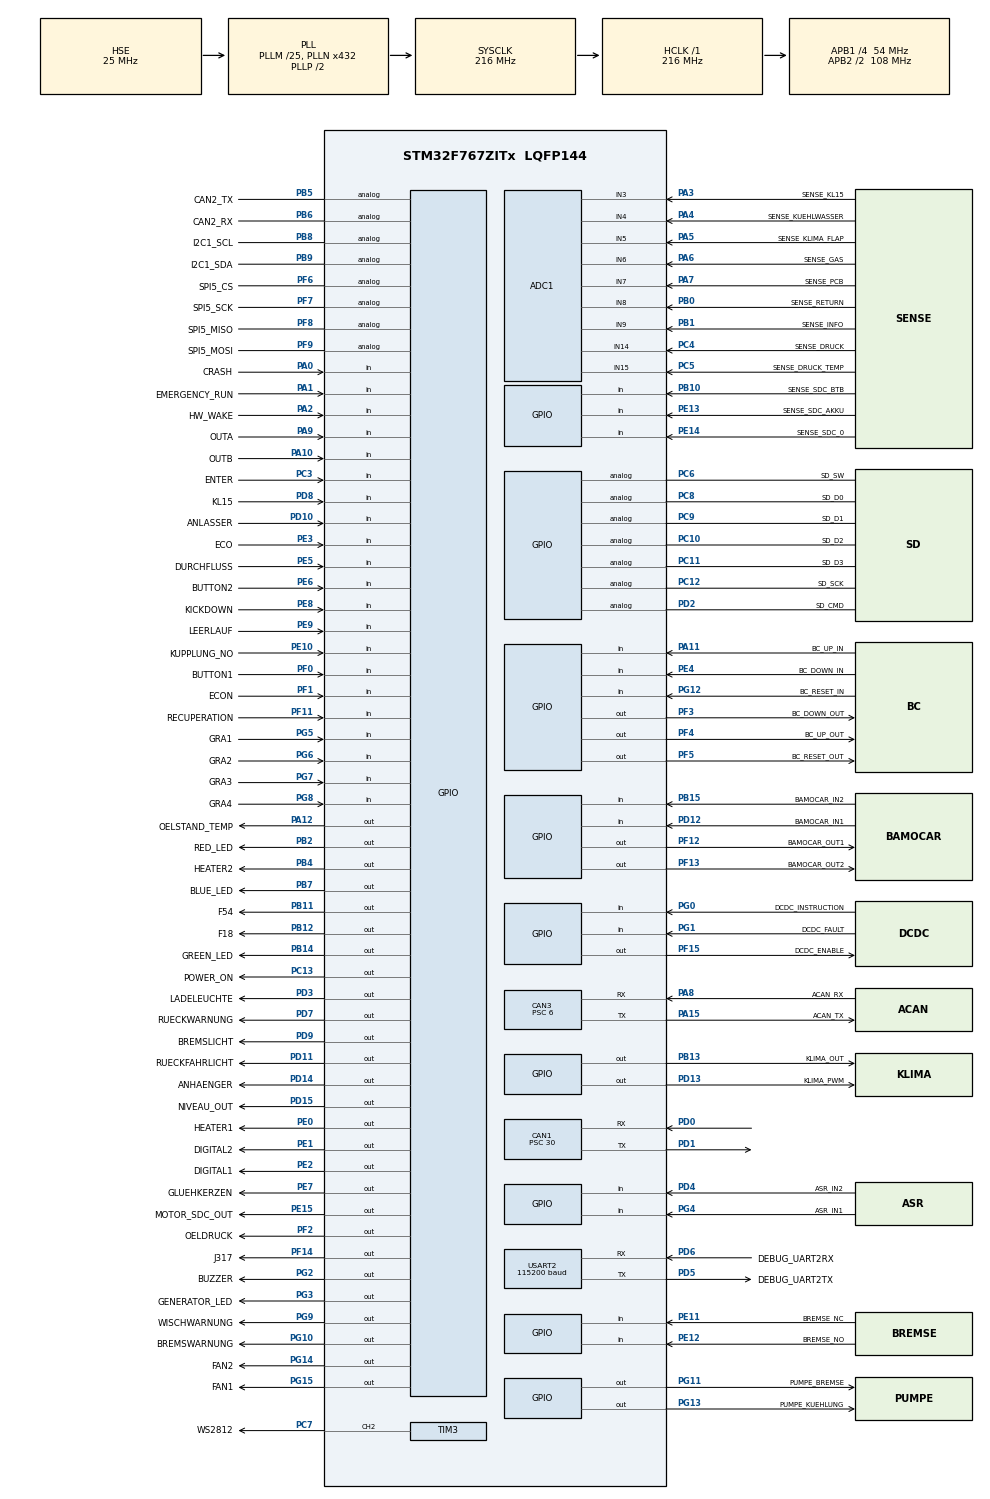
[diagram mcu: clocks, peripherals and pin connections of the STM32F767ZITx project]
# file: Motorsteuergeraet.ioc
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ADC1.Channel-0\#ChannelRegularConversion=ADC_CHANNEL_14
ADC1.ClockPrescaler=ADC_CLOCK_SYNC_PCLK_DIV4
ADC1.InjNumberOfConversion=0
ADC1.NbrOfConversion=1
ADC1.NbrOfConversionFlag=1
ADC1.Rank-0\#ChannelRegularConversion=1
ADC1.SamplingTime-0\#ChannelRegularConversion=ADC_SAMPLETIME_15CYCLES
ADC1.master=1
CAN1.BS1=CAN_BS1_15TQ
CAN1.BS2=CAN_BS2_2TQ
CAN1.CalculateBaudRate=100000
CAN1.CalculateTimeBit=10000
CAN1.CalculateTimeQuantum=555.5555555555555
CAN1.Prescaler=30
CAN3.BS1=CAN_BS1_15TQ
CAN3.BS2=CAN_BS2_2TQ
CAN3.CalculateBaudRate=500000
CAN3.CalculateTimeBit=2000
CAN3.CalculateTimeQuantum=111.11111111111111
CAN3.NART=ENABLE
CAN3.Prescaler=6
Dma.Request0=TIM3_CH2
Dma.TIM3_CH2.0.Direction=DMA_MEMORY_TO_PERIPH
Dma.TIM3_CH2.0.FIFOMode=DMA_FIFOMODE_DISABLE
Dma.TIM3_CH2.0.Instance=DMA1_Stream5
Dma.TIM3_CH2.0.MemDataAlignment=DMA_MDATAALIGN_HALFWORD
Dma.TIM3_CH2.0.MemInc=DMA_MINC_ENABLE
Dma.TIM3_CH2.0.Mode=DMA_NORMAL
Dma.TIM3_CH2.0.PeriphDataAlignment=DMA_PDATAALIGN_HALFWORD
Dma.TIM3_CH2.0.PeriphInc=DMA_PINC_DISABLE
Dma.TIM3_CH2.0.Priority=DMA_PRIORITY_HIGH
Mcu.Family=STM32F7
Mcu.Name=STM32F767ZITx
Mcu.Package=LQFP144
NVIC.CAN3_RX0_IRQn=true\:0\:0\:false\:false\:false\:true\:true\:true
NVIC.CAN3_TX_IRQn=true\:15\:0\:true\:false\:false\:true\:true\:true
NVIC.DMA1_Stream5_IRQn=true\:0\:0\:false\:false\:true\:false\:true\:true
NVIC.PriorityGroup=NVIC_PRIORITYGROUP_4
NVIC.TIM3_IRQn=true\:0\:0\:false\:false\:true\:true\:true\:true
NVIC.TIM6_DAC_IRQn=true\:0\:0\:false\:false\:true\:true\:true\:true
NVIC.USART2_IRQn=true\:0\:0\:false\:false\:true\:true\:true\:true
PA0/WKUP.GPIO_Label=CRASH
PA0/WKUP.Signal=GPIO_Input
PA1.GPIO_Label=EMERGENCY_RUN
PA1.Signal=GPIO_Input
PA10.GPIO_Label=OUTB
PA10.Signal=GPIO_Input
PA11.GPIO_Label=BC_UP_IN
PA11.Signal=GPIO_Input
PA12.GPIO_Label=OELSTAND_TEMP
PA12.Signal=GPIO_Output
PA13.Mode=Trace_Asynchronous_SW
PA13.Signal=SYS_JTMS-SWDIO
PA14.Mode=Trace_Asynchronous_SW
PA14.Signal=SYS_JTCK-SWCLK
PA15.GPIO_Label=ACAN_TX
PA15.Mode=CAN_Activate
PA15.Signal=CAN3_TX
PA2.GPIO_Label=HW_WAKE
PA2.Signal=GPIO_Input
PA3.GPIO_Label=SENSE_KL15
PA3.Signal=SharedAnalog_PA3
PA4.GPIO_Label=SENSE_KUEHLWASSER
PA4.Signal=SharedAnalog_PA4
PA5.GPIO_Label=SENSE_KLIMA_FLAP
PA5.Signal=SharedAnalog_PA5
PA6.GPIO_Label=SENSE_GAS
PA6.Signal=SharedAnalog_PA6
PA7.GPIO_Label=SENSE_PCB
PA7.Signal=SharedAnalog_PA7
PA8.GPIO_Label=ACAN_RX
PA8.Mode=CAN_Activate
PA8.Signal=CAN3_RX
PA9.GPIO_Label=OUTA
PA9.Signal=GPIO_Input
PB0.GPIO_Label=SENSE_RETURN
PB0.Signal=SharedAnalog_PB0
PB1.GPIO_Label=SENSE_INFO
PB1.Signal=SharedAnalog_PB1
PB10.GPIO_Label=SENSE_SDC_BTB
PB10.Signal=GPIO_Input
PB11.GPIO_Label=F54
PB11.Signal=GPIO_Output
PB12.GPIO_Label=F18
PB12.Signal=GPIO_Output
PB13.GPIO_Label=KLIMA_OUT
PB13.Signal=GPIO_Output
PB14.GPIO_Label=GREEN_LED
PB14.Signal=GPIO_Output
PB15.GPIO_Label=BAMOCAR_IN2
PB15.Signal=GPIO_Input
PB2.GPIO_Label=RED_LED
PB2.Signal=GPIO_Output
PB3.Mode=Trace_Asynchronous_SW
PB3.Signal=SYS_JTDO-SWO
PB4.GPIO_Label=HEATER2
PB4.Signal=GPIO_Output
PB5.GPIO_Label=CAN2_TX
PB5.Signal=GPIO_Analog
PB6.GPIO_Label=CAN2_RX
PB6.Signal=GPIO_Analog
PB7.GPIO_Label=BLUE_LED
PB7.Signal=GPIO_Output
PB8.GPIO_Label=I2C1_SCL
PB8.Signal=GPIO_Analog
PB9.GPIO_Label=I2C1_SDA
PB9.Signal=GPIO_Analog
PC10.GPIO_Label=SD_D2
PC10.Signal=GPIO_Analog
PC11.GPIO_Label=SD_D3
PC11.Signal=GPIO_Analog
PC12.GPIO_Label=SD_SCK
PC12.Signal=GPIO_Analog
PC13.GPIO_Label=POWER_ON
PC13.Signal=GPIO_Output
PC3.GPIO_Label=ENTER
PC3.Signal=GPIO_Input
PC4.GPIO_Label=SENSE_DRUCK
PC4.Signal=SharedAnalog_PC4
PC5.GPIO_Label=SENSE_DRUCK_TEMP
PC5.Signal=SharedAnalog_PC5
PC6.GPIO_Label=SD_SW
PC6.Signal=GPIO_Analog
PC7.GPIO_Label=WS2812
PC7.GPIO_Speed=GPIO_SPEED_FREQ_HIGH
PC7.Signal=S_TIM3_CH2
PC8.GPIO_Label=SD_D0
PC8.Signal=GPIO_Analog
PC9.GPIO_Label=SD_D1
PC9.Signal=GPIO_Analog
PD0.Mode=CAN_Activate
PD0.Signal=CAN1_RX
PD1.Mode=CAN_Activate
PD1.Signal=CAN1_TX
PD10.GPIO_Label=ANLASSER
PD10.Signal=GPIO_Input
PD11.GPIO_Label=RUECKFAHRLICHT
PD11.Signal=GPIO_Output
PD12.GPIO_Label=BAMOCAR_IN1
PD12.Signal=GPIO_Input
PD13.GPIO_Label=KLIMA_PWM
PD13.Signal=GPIO_Output
PD14.GPIO_Label=ANHAENGER
PD14.Signal=GPIO_Output
PD15.GPIO_Label=NIVEAU_OUT
PD15.Signal=GPIO_Output
PD2.GPIO_Label=SD_CMD
PD2.Signal=GPIO_Analog
PD3.GPIO_Label=LADELEUCHTE
PD3.Signal=GPIO_Output
PD4.GPIO_Label=ASR_IN2
PD4.Signal=GPIO_Input
PD5.GPIO_Label=DEBUG_UART2TX
PD5.Mode=Asynchronous
PD5.Signal=USART2_TX
PD6.GPIO_Label=DEBUG_UART2RX
PD6.Mode=Asynchronous
PD6.Signal=USART2_RX
PD7.GPIO_Label=RUECKWARNUNG
PD7.Signal=GPIO_Output
PD8.GPIO_Label=KL15
PD8.Signal=GPIO_Input
PD9.GPIO_Label=BREMSLICHT
PD9.Signal=GPIO_Output
PE0.GPIO_Label=HEATER1
PE0.Signal=GPIO_Output
PE1.GPIO_Label=DIGITAL2
PE1.Signal=GPIO_Output
PE10.GPIO_Label=KUPPLUNG_NO
PE10.Signal=GPIO_Input
PE11.GPIO_Label=BREMSE_NC
PE11.Signal=GPIO_Input
PE12.GPIO_Label=BREMSE_NO
PE12.Signal=GPIO_Input
PE13.GPIO_Label=SENSE_SDC_AKKU
PE13.Signal=GPIO_Input
PE14.GPIO_Label=SENSE_SDC_0
PE14.Signal=GPIO_Input
PE15.GPIO_Label=MOTOR_SDC_OUT
PE15.Signal=GPIO_Output
PE2.GPIO_Label=DIGITAL1
PE2.Signal=GPIO_Output
PE3.GPIO_Label=ECO
PE3.Signal=GPIO_Input
PE4.GPIO_Label=BC_DOWN_IN
PE4.Signal=GPIO_Input
PE5.GPIO_Label=DURCHFLUSS
PE5.Signal=GPIO_Input
PE6.GPIO_Label=BUTTON2
PE6.Signal=GPIO_Input
PE7.GPIO_Label=GLUEHKERZEN
PE7.Signal=GPIO_Output
PE8.GPIO_Label=KICKDOWN
PE8.Signal=GPIO_Input
PE9.GPIO_Label=LEERLAUF
PE9.Signal=GPIO_Input
PF0.GPIO_Label=BUTTON1
PF0.Signal=GPIO_Input
PF1.GPIO_Label=ECON
PF1.Signal=GPIO_Input
PF11.GPIO_Label=RECUPERATION
PF11.Signal=GPIO_Input
PF12.GPIO_Label=BAMOCAR_OUT1
PF12.Signal=GPIO_Output
PF13.GPIO_Label=BAMOCAR_OUT2
PF13.Signal=GPIO_Output
PF14.GPIO_Label=J317
PF14.Signal=GPIO_Output
PF15.GPIO_Label=DCDC_ENABLE
PF15.Signal=GPIO_Output
PF2.GPIO_Label=OELDRUCK
PF2.Signal=GPIO_Output
PF3.GPIO_Label=BC_DOWN_OUT
PF3.Signal=GPIO_Output
PF4.GPIO_Label=BC_UP_OUT
PF4.Signal=GPIO_Output
PF5.GPIO_Label=BC_RESET_OUT
PF5.Signal=GPIO_Output
PF6.GPIO_Label=SPI5_CS
PF6.Signal=GPIO_Analog
PF7.GPIO_Label=SPI5_SCK
PF7.Signal=GPIO_Analog
PF8.GPIO_Label=SPI5_MISO
PF8.Signal=GPIO_Analog
PF9.GPIO_Label=SPI5_MOSI
PF9.Signal=GPIO_Analog
PG0.GPIO_Label=DCDC_INSTRUCTION
PG0.Signal=GPIO_Input
PG1.GPIO_Label=DCDC_FAULT
PG1.Signal=GPIO_Input
PG10.GPIO_Label=BREMSWARNUNG
PG10.Signal=GPIO_Output
PG11.GPIO_Label=PUMPE_BREMSE
PG11.Signal=GPIO_Output
PG12.GPIO_Label=BC_RESET_IN
PG12.Signal=GPIO_Input
PG13.GPIO_Label=PUMPE_KUEHLUNG
PG13.Signal=GPIO_Output
PG14.GPIO_Label=FAN2
PG14.Signal=GPIO_Output
PG15.GPIO_Label=FAN1
PG15.Signal=GPIO_Output
PG2.GPIO_Label=BUZZER
PG2.Signal=GPIO_Output
PG3.GPIO_Label=GENERATOR_LED
PG3.Signal=GPIO_Output
PG4.GPIO_Label=ASR_IN1
PG4.Signal=GPIO_Input
PG5.GPIO_Label=GRA1
PG5.Signal=GPIO_Input
PG6.GPIO_Label=GRA2
PG6.Signal=GPIO_Input
PG7.GPIO_Label=GRA3
PG7.Signal=GPIO_Input
PG8.GPIO_Label=GRA4
PG8.Signal=GPIO_Input
PG9.GPIO_Label=WISCHWARNUNG
PG9.Signal=GPIO_Output
PH0/OSC_IN.Mode=HSE-External-Oscillator
PH0/OSC_IN.Signal=RCC_OSC_IN
PH1/OSC_OUT.Mode=HSE-External-Oscillator
PH1/OSC_OUT.Signal=RCC_OSC_OUT
ProjectManager.HeapSize=0x200
ProjectManager.StackSize=0x400
ProjectManager.TargetToolchain=STM32CubeIDE
RCC.AHBFreq_Value=216000000
RCC.APB1CLKDivider=RCC_HCLK_DIV4
RCC.APB1Freq_Value=54000000
RCC.APB1TimFreq_Value=108000000
RCC.APB2CLKDivider=RCC_HCLK_DIV2
RCC.APB2Freq_Value=108000000
RCC.APB2TimFreq_Value=216000000
RCC.CortexFreq_Value=216000000
RCC.HCLKFreq_Value=216000000
RCC.HSE_VALUE=25000000
RCC.HSI_VALUE=16000000
RCC.LSE_VALUE=32768
RCC.PLLM=25
RCC.PLLN=432
RCC.PLLSourceVirtual=RCC_PLLSOURCE_HSE
RCC.SYSCLKFreq_VALUE=216000000
RCC.SYSCLKSource=RCC_SYSCLKSOURCE_PLLCLK
RCC.USBFreq_Value=216000000
RCC.VCOOutputFreq_Value=432000000
SH.S_TIM3_CH2.0=TIM3_CH2,PWM Generation2 CH2
SH.SharedAnalog_PA3.0=GPIO_Analog
SH.SharedAnalog_PA3.1=ADC1_IN3,IN3
SH.SharedAnalog_PA4.0=GPIO_Analog
SH.SharedAnalog_PA4.1=ADC1_IN4,IN4
SH.SharedAnalog_PA5.0=GPIO_Analog
SH.SharedAnalog_PA5.1=ADC1_IN5,IN5
SH.SharedAnalog_PA6.0=GPIO_Analog
SH.SharedAnalog_PA6.1=ADC1_IN6,IN6
SH.SharedAnalog_PA7.0=GPIO_Analog
SH.SharedAnalog_PA7.1=ADC1_IN7,IN7
SH.SharedAnalog_PB0.0=GPIO_Analog
SH.SharedAnalog_PB0.1=ADC1_IN8,IN8
SH.SharedAnalog_PB1.0=GPIO_Analog
SH.SharedAnalog_PB1.1=ADC1_IN9,IN9
SH.SharedAnalog_PC4.0=GPIO_Analog
SH.SharedAnalog_PC4.1=ADC1_IN14,IN14
SH.SharedAnalog_PC5.0=GPIO_Analog
SH.SharedAnalog_PC5.1=ADC1_IN15,IN15
TIM3.AutoReloadPreload=TIM_AUTORELOAD_PRELOAD_DISABLE
TIM3.Channel-PWM\ Generation2\ CH2=TIM_CHANNEL_2
TIM3.OC2Preload_PWM=ENABLE
TIM3.OCFastMode_PWM-PWM\ Generation2\ CH2=TIM_OCFAST_ENABLE
TIM3.OCMode_PWM-PWM\ Generation2\ CH2=TIM_OCMODE_PWM1
TIM3.OCPolarity_2=TIM_OCPOLARITY_LOW
TIM3.Period=135 - 1
TIM6.Period=4000 - 1
TIM6.Prescaler=27 - 1
USART2.BaudRate=115200
USART2.VirtualMode-Asynchronous=VM_ASYNC
VP_ADC1_TempSens_Input.Mode=IN-TempSens
VP_TIM3_VS_ClockSourceINT.Mode=Internal
VP_TIM6_VS_ClockSourceINT.Mode=Enable_Timer
board=custom

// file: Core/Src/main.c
/* USER CODE BEGIN Header */
/**
  ******************************************************************************
  * @file           : main.c
  * @brief          : Main program body
  ******************************************************************************
  * @attention
  *
  * <h2><center>&copy; Copyright (c) 2021 STMicroelectronics.
  * All rights reserved.</center></h2>
  *
  * This software component is licensed by ST under BSD 3-Clause license,
  * the "License"; You may not use this file except in compliance with the
  * License. You may obtain a copy of the License at:
  *                        opensource.org/licenses/BSD-3-Clause
  *
  ******************************************************************************
  */
/* USER CODE END Header */
#include "main.h"
#include "adc.h"
#include "can.h"
#include "dma.h"
#include "tim.h"
#include "usart.h"
#include "gpio.h"

/* USER CODE BEGIN Includes */
#include "Motorsteuergeraet.h"
/* USER CODE END Includes */

/* USER CODE BEGIN PTD */
// TODO: OELDRUCKSCHALTER
// FIXME: CAN Bus (CAN-Bus braucht Ablaufprogramm)
// xxx: Schlechte Performance
/* USER CODE END PTD */

/* USER CODE BEGIN PV */
// Motorsteuergeraet Statevariable
Motor_state mStrg_state = {{Start, true, false, false, false}};
static uint32_t timeError = 0, timeWarning = 0;
static uint32_t longerror = 0, longwarning = 0;

// Fehler Speicher CAN-Bus
uint8_t  can_online = 0;

// Millisekunden Flag fuer PWM Task
volatile uint8_t millisekunden_flag = 0;											// Flag fuer Millisekungen Timer Task

// Motor CAN Variablen
motor280_tag motor280;																// Daten der CAN-Nachricht 280
//motor288_tag motor288;																// Daten der CAN-Nachricht 288
//motor380_tag motor380;																// Daten der CAN-Nachricht 380
//motor388_tag motor388;																// Daten der CAN-Nachricht 388
motor480_tag motor480;																// Daten der CAN-Nachricht 480
//motor488_tag motor488;																// Daten der CAN-Nachricht 488
//motor580_tag motor580;																// Daten der CAN-Nachricht 580

// ADC Array
uint16_t ADC_VAL[10] = {0};

// Mittelwert Gaspedal
uint16_t gas_mean = 0;
/* USER CODE END PV */

void SystemClock_Config(void);
/* USER CODE BEGIN PFP */
void checkSDC(void);
void sortCAN(void);
void setState(uint8_t State);
void setStatus(uint8_t Status);
/* USER CODE END PFP */

int main(void)
{

  /* USER CODE BEGIN 1 */
	// Motorsteuergeraet Statemaschine Zeitvariablen
	uint32_t timeStandby = 0, timeErrorLED = 0;

	// Timer Task Variablen (PWM)
	uint8_t task = 0;
	uint16_t count = 0;

	// Motorsteuergeraet CAN-Bus Zeitvariable, Errorvariable
	uint32_t timeBAMO = 0, timeBMS = 0, timeStromHV = 0, timeStromLV = 0, timeKombi = 0;

	// CAN-Bus Receive Message
	CAN_message_t RxMessage;

	// ADC Wert Gaspedal
	uint16_t gas_adc = 0;

	// WS2812 LED
	uint8_t WS2812_update = 0;

	// Anforderung BMS Status fuer Drive Modus
	Motor_state BMS_State = {{Start, true, false, false, false}};
  /* USER CODE END 1 */

  /* MCU Configuration--------------------------------------------------------*/

  /* Reset of all peripherals, Initializes the Flash interface and the Systick. */
  HAL_Init();

  /* Configure the system clock */
  SystemClock_Config();

  /* USER CODE BEGIN SysInit */
  MX_USART2_UART_Init();

#ifdef DEBUG
	app_info();
	HAL_Delay(3000);
#endif

	uartTransmit("Start\n", 6);
  /* USER CODE END SysInit */

  /* Initialize all configured peripherals */
  MX_GPIO_Init();
  MX_DMA_Init();
  MX_ADC1_Init();
  MX_CAN1_Init();
  MX_TIM6_Init();
  MX_TIM3_Init();
  MX_CAN3_Init();
  MX_USART2_UART_Init();
  /* USER CODE BEGIN 2 */

	SetLED_color(1, WS2812_ORANGE);
	WS2812_Send_Wait();

	// Starte Timer 6 Interrupt
	HAL_TIM_Base_Start_IT(&htim6);

	leuchten_out.Anhaenger = true;
	leuchten_out.Niveau = true;
	HAL_GPIO_WritePin(ANHAENGER_GPIO_Port, ANHAENGER_Pin, leuchten_out.Anhaenger);
	HAL_GPIO_WritePin(NIVEAU_OUT_GPIO_Port, NIVEAU_OUT_Pin, leuchten_out.Niveau);

#ifdef DEBUG
	#define MAINWHILE			"\nStarte While Schleife\n"
	uartTransmit(MAINWHILE, sizeof(MAINWHILE));
#endif

	// CAN-Bus initialisieren
	CANinit(RX_SIZE_16, TX_SIZE_16);
	CAN_config();

	for (uint8_t j = 0; j < ANZAHL_OUTPUT_PAKETE; j++)
	{
		CAN_Output_PaketListe[j].msg.buf[0] = 0;
		CAN_Output_PaketListe[j].msg.buf[1] = 0;
		CAN_Output_PaketListe[j].msg.buf[2] = 0;
		CAN_Output_PaketListe[j].msg.buf[3] = 0;
		CAN_Output_PaketListe[j].msg.buf[4] = 0;
		CAN_Output_PaketListe[j].msg.buf[5] = 0;
		CAN_Output_PaketListe[j].msg.buf[6] = 0;
		CAN_Output_PaketListe[j].msg.buf[7] = 0;
	}

	// Wenn Tischaufbau dann CAN-Nachricht fuer Lenkung senden
#if TISCHAUFBAU == 1
	CAN_Output_PaketListe[9].msg.buf[0] = 0;
	CAN_Output_PaketListe[9].msg.buf[1] = 1;
#endif

	SetLED_color(1, WS2812_GREEN);
	WS2812_update = 1;

	setState(Ready);
  /* USER CODE END 2 */

  /* Infinite loop */
  while (1)
  {

    /* USER CODE BEGIN 3 */
	  // Alle Eingaenge einlesen
	  readall_inputs();

	  // Alle ADC einlesen
	  ADC_VAL[0] = ADC_Bremsdruck();
	  ADC_VAL[1] = ADC_Bremsdrucktemperatur();
	  ADC_VAL[2] = ADC_STMTemperatur();
	  ADC_VAL[3] = ADC_PCBTemperatur();
	  ADC_VAL[4] = ADC_KL15();
	  ADC_VAL[5] = ADC_Klimaflap();
	  ADC_VAL[6] = ADC_Info();
	  ADC_VAL[7] = ADC_Return();
	  ADC_VAL[8] = ADC_Kuhlwassertemperatur();
	  ADC_VAL[9] = ADC_Gaspedal();

	  // Sortiere CAN-Daten auf CAN-Buffer
	  sortCAN();

	  // Lese CAN-Nachrichten ein
	  if (CAN_available() >= 1)
	  {
		  CANread(&RxMessage);

		  switch (RxMessage.id)
		  {
#if BAMOCAR_AVAILIBLE == 1
			  // Bamocar ID
			  case BAMOCAR_CAN_RX:
			  {
				  can_online |= (1 << 0);
				  timeBAMO = millis();
				  BAMOCAN_ID(&RxMessage.buf[0], RxMessage.len);
				  break;
			  }
#endif

#if BMS_AVAILIBLE == 1
			  // Batteriemanagement Status ID
			  case BMS_CAN_STATUS:
			  {
				  BMS_State.status = RxMessage.buf[0];

				  timeBMS = millis();
				  can_online |= (1 << 1);
				  break;
			  }
#endif

#if STROM_HV_AVAILIBLE == 1
			  // Stromsensor
			  case STROM_HV_CAN_I:
			  {
				  can_online |= (1 << 2);
				  timeStromHV = millis();
				  break;
			  }
#endif

#if STROM_LV_AVAILIBLE == 1
			  // Stromsensor
			  case STROM_LV_CAN_I:
			  {
				  can_online |= (1 << 3);
				  timeStromHV = millis();
				  break;
			  }
#endif

#if KOMBIINSTRUMENT_AVAILIBLE == 1
			  // Stromsensor
			  case KOMBI2_CAN:
			  {
				  can_online |= (1 << 4);
				  timeKombi = millis();

				  setStatus(StateNormal);

				  break;
			  }
#endif

			  // Alle anderen Pakete laufen in leere und werden ignoriert
			  default:
			  {
				  break;
			  }
		  }
	  }

#if BAMOCAR_AVAILIBLE == 1
	  // Wenn Timeoutzeit ueberschritten, Bamocar CAN-Timeout
	  if ((mStrg_state.State > Ready) && (millis() > (timeBAMO + CAN_TIMEOUT)))
	  {
		  can_online &= ~(1 << 0);
		  longwarning |= (1 << 0);

		  setStatus(StateWarning);
	  }
#endif

#if BMS_AVAILIBLE == 1
	  // Wenn Timeoutzeit ueberschritten, BMS CAN-Timeout
	  if ((mStrg_state.State > Ready) && (millis() > (timeBMS + CAN_TIMEOUT)))
	  {
		  can_online &= ~(1 << 1);
		  longwarning |= (1 << 0);

		  setStatus(StateWarning);
	  }
#endif

#if STROM_HV_AVAILIBLE == 1
	  // Wenn Timeoutzeit ueberschritten, Stromsensor HV CAN-Timeout
	  if ((mStrg_state.State > Ready) && (millis() > (timeStromHV + CAN_TIMEOUT)))
	  {
		  can_online &= ~(1 << 2);
		  longwarning |= (1 << 0);

		  setStatus(StateWarning);
	  }
#endif

#if STROM_LV_AVAILIBLE == 1
	  // Wenn Timeoutzeit ueberschritten, Stromsensor LV CAN-Timeout
	  if ((mStrg_state.State > Ready) && (millis() > (timeStromLV + CAN_TIMEOUT)))
	  {
		  can_online &= ~(1 << 3);
		  longwarning |= (1 << 0);

		  setStatus(StateWarning);
	  }
#endif

#if KOMBIINSTRUMENT_AVAILIBLE == 1
	  // Wenn Timeoutzeit ueberschritten, Kombiinstrument
	  if ((mStrg_state.State > Ready) && (millis() > (timeKombi + CAN_TIMEOUT)))
	  {
		  can_online &= ~(1 << 4);
		  longwarning |= (1 << 0);

		  setStatus(StateWarning);
	  }
#endif

	  // PWM Oelstandsensor Kombiinstrument ausgeben
	  pwm_oelstand(count);

	  // Task wird jede Millisekunde ausgefuehrt
	  if (millisekunden_flag == 1)
	  {
		  count++;																	// Zaehler count hochzaehlen
		  millisekunden_flag = 0;													// Setze Millisekunden-Flag zurueck

		  // Setze Flag start, nur wenn millisekunden Flag gesetzt war
		  task = 1;
	  }

	  // Zuruecksetzen der Countervariable fuer pwm_Oelstand
	  if (((count % 400) == 0) && (task == 1))
	  {
		  // Variable count auf 0 zuruecksetzen
		  count = 0;
	  }

	  // Crash Ausgeloest
	  if (system_in.Crash != 1)
	  {
		  setStatus(CriticalError);
	  }

	  // Wenn Statemaschine nicht im Standby ist
	  if (mStrg_state.State != Standby)
	  {
		  // Schreibe alle CAN-NAchrichten auf BUS, wenn nicht im Standby
		  CANwork();

		  // Shutdown-Circuit checken
		  checkSDC();
	  }

	  // Statemaschine keine Fehler
	  if (mStrg_state.Normal)
	  {
		  leuchten_out.RedLed = false;
		  leuchten_out.GreenLed = true;

		  motor480.MotorLED = false;
	  }

	  // Statemaschine hat Warnungen
	  if (mStrg_state.Warning)
	  {
		  if (millis() - timeErrorLED > 1000)
		  {
			  leuchten_out.RedLed = !leuchten_out.RedLed;

			  motor480.MotorLED = !motor480.MotorLED;
			  timeErrorLED = millis();
		  }

		  leuchten_out.GreenLed = true;
	  }

	  // Statemaschine hat Fehler
	  if (mStrg_state.Error)
	  {
		  if (millis() - timeErrorLED > 1000)
		  {
			  leuchten_out.RedLed = !leuchten_out.RedLed;
			  timeErrorLED = millis();
		  }

		  leuchten_out.GreenLed = false;

		  motor480.MotorLED = true;
	  }

	  // Statemaschine hat Kritische Fehler
	  if (mStrg_state.CriticalError)
	  {
		  leuchten_out.RedLed = true;
		  leuchten_out.Ladeleuchte = false;
		  leuchten_out.GreenLed = false;

		  motor480.MotorLED = true;

		  system_out.MotorSDC = false;
	  }

	  // Statemaschine von Motorsteuergeraet
	  switch (mStrg_state.State)
	  {
		  // State Ready, Vorbereiten des Motorsteuergeraetes
		  case Ready:
		  {
			  // LEDs testen
			  uartTransmit("Testen der PCB und Cockpit LEDs\n", 32);
			  testPCB_Leds();
			  testCockpit_Leds();

			  // Testen der Versorgungsspannung am Shutdown Circuit
			  uartTransmit("Testen der SDC-Sicherung\n", 25);
			  //testSDC();

			  // Alle Fehler am Cockpit loeschen
			  uartTransmit("Cockpit LEDs standardmaessig ausschalten\n", 41);
			  cockpit_default();

			  timeBMS = millis();
			  timeBAMO = millis();
			  timeStromHV = millis();
			  timeStromLV = millis();
			  timeKombi = millis();

			  setState(KL15);

			  break;
		  }

		  // State KL15, wenn Schluessel auf Position 2, KL15 einschalten
		  case KL15:
		  {
			  // Wenn Schluessel auf Position 3 geschaltet wird, nur einmal moeglich
			  if ((system_in.Anlasser != 1) || ((sdc_in.Anlasser == 1) && (komfort_in.ASR1 == 1) && (millis() > (timeStandby + 3000))))
			  {
				  // Solange kein kritischer Fehler auftritt
				  if (!(mStrg_state.CriticalError))
				  {
					  setState(Anlassen);

					  // Anlasser Zustand abspeichern
					  sdc_in.Anlasser = true;

					  // LED in Cockpit aktivieren
					  motor480.VorgluehenLED = true;

					  // Motor Shutdown-Circuit aktivieren, wenn OK
					  system_out.MotorSDC = true;
				  }

				  // Pumpe, Vakuumpumpe, Bamocar einschalten
				  // system_out.Gluehkerzen = 1;
			  }

			  // Falls KL15 abfaellt und der Schluessel abgezogen wird
			  if (system_in.KL15 == 1)
			  {
				  setState(Standby);

				  system_out.MotorSDC = false;
				  sdc_in.Anlasser = false;
				  timeStandby = millis();
			  }

			  break;
		  }

		  // State Anlassen, wenn Schluessel auf Position 3 und keine kritischen Fehler, Anlasser einschalten
		  case Anlassen:
		  {
			  // Kupplung und Bremse getreten
			  if ((system_in.Kupplung != 1) && (system_in.BremseNO != 1) && (system_in.BremseNC == 1))
			  {
				  setState(Precharge);
			  }

			  // Falls KL15 abfaellt und der Schluessel abgezogen wird
			  if (system_in.KL15 == 1)
			  {
				  setState(Standby);

				  system_out.MotorSDC = false;
				  sdc_in.Anlasser = false;
				  timeStandby = millis();
			  }

			  break;
		  }

		  // State Precharge, wenn Bremse beim Anlassen oder danach getreten ist
		  case Precharge:
		  {
			  // Abfrage Shutdown-Circuit
			  if ((sdc_in.SDC0 != 1) && (sdc_in.BTB_SDC != 1) && (sdc_in.AkkuSDC != 1))
			  {
				  // ReadyToDrive Sound abspielen und warten, ob abgeschlossen werden kann
				  if (playRTDS() == true)
				  {

					  setState(ReadyToDrive);

					  motor480.VorgluehenLED = false;

					  timeStandby = millis();
				  }
				  else
				  {
					  mStrg_state.State = KL15;
					  system_out.MotorSDC = false;
					  sdc_in.Anlasser = false;
				  }
			  }

			  // Falls KL15 abfaellt und der Schluessel abgezogen wird
			  if (system_in.KL15 == 1)
			  {
				  setState(Standby);

				  system_out.MotorSDC = false;
				  sdc_in.Anlasser = false;
				  timeStandby = millis();
			  }

			  break;
		  }

		  // State ReadyToDrive, wenn SDC Ok ist und Vorgeladen wurde
		  case ReadyToDrive:
		  {
			  // Bei Tasterbetaetigung umschalten in Drive Modus
			  if (((BMS_State.State == ReadyToDrive) || (BMS_State.State == Drive)) && (komfort_in.ASR1 == 1) && (millis() > (timeStandby + 3000)))
			  {
				  setState(Drive);

				  SetLED_color(1, WS2812_RED);
				  WS2812_update = 1;

				  timeStandby = millis();
			  }

			  // Falls KL15 abfaellt und der Schluessel abgezogen wird
			  if (system_in.KL15 == 1)
			  {
				  setState(Standby);

				  system_out.MotorSDC = false;
				  sdc_in.Anlasser = false;
				  timeStandby = millis();
			  }

			  break;
		  }

		  // State Drive, wenn Fahrmodus manuel aktiviert wird
		  case Drive:
		  {
			   gas_adc = readTrottle(ADC_VAL[9]);

			  // Abfrage ob Mittelwertbildung
			  if (gas_adc > 0)														// Wenn Gaspedal Plausible dann Mittelwertbildung
			  {
				  // Mittelwert bilden (https://nestedsoftware.com/2018/03/20/calculating-a-moving-average-on-streaming-data-5a7k.22879.html)
				  // Mittelwertbildung aus 10 Werten (Weniger die 10 verkleineren, Mehr die 10 vergroeßern)
				  gas_mean = (gas_mean + ((gas_adc - gas_mean)/10));
			  }
			  else																	// Wenn Gaspedal unplausible oder Kupplung getreten
			  {
				  gas_mean = 0;
			  }

			  // Todo: Wenn Drehzahl zu hoch dann Fehler Cockpit (Oelstand, Bremse)
			  CAN_Output_PaketListe[8].msg.buf[0] = BAMOCAR_REG_TORQUE_SETPOINT;
			  CAN_Output_PaketListe[8].msg.buf[1] = gas_mean;
			  CAN_Output_PaketListe[8].msg.buf[2] = (gas_mean >> 8);
			  CAN_Output_PaketListe[8].allowed = true;

			  motor280.Drehzahl = (gas_mean * 5);

			  if ((komfort_in.ASR1 == 1) && (millis() > (timeStandby + 3000)))
			  {
				  setState(KL15);

				  system_out.MotorSDC = false;

				  SetLED_color(1, WS2812_GREEN);
				  WS2812_update = 1;

				  CAN_Output_PaketListe[8].msg.buf[0] = BAMOCAR_REG_TORQUE_SETPOINT;
				  CAN_Output_PaketListe[8].msg.buf[1] = 0;
				  CAN_Output_PaketListe[8].msg.buf[2] = 0;
				  CAN_Output_PaketListe[8].allowed = false;

				  motor280.Drehzahl = 0;

				  timeStandby = millis();
			  }

			  // Falls KL15 abfaellt und der Schluessel abgezogen wird
			  if (system_in.KL15 == 1)
			  {
				  setState(Standby);

				  system_out.MotorSDC = false;
				  sdc_in.Anlasser = false;

				  SetLED_color(1, WS2812_GREEN);
				  WS2812_update = 1;

				  CAN_Output_PaketListe[8].msg.buf[0] = BAMOCAR_REG_TORQUE_SETPOINT;
				  CAN_Output_PaketListe[8].msg.buf[1] = 0;
				  CAN_Output_PaketListe[8].msg.buf[2] = 0;
				  CAN_Output_PaketListe[8].allowed = false;

				  motor280.Drehzahl = 0;

				  timeStandby = millis();
			  }

			  break;
		  }

		  // State Standby, wenn Schluessel gezogen wird, KL15 ausschalten
		  case Standby:
		  {
			  // Gluehkerzenrelais nach 1min abschalten, erst nach der Pumpe moeglich
			  if ((highcurrent_out.Pumpe_Kuhlung == false) && (millis() > (timeStandby + PUMPTIME + 1000)))
			  {
				  system_out.Gluehkerzen = false;
			  }

			  // Pumpe nach 1min abschalten
			  if ((highcurrent_out.Pumpe_Kuhlung == true) && (millis() > (timeStandby + PUMPTIME)))
			  {
				  highcurrent_out.Pumpe_Kuhlung = false;
			  }

			  // Fuer 5min warten und mStrg weiterhin aktiv halten
			  if (millis() > (timeStandby + MOTORTIME))
			  {
				  setState(Ausschalten);
			  }
			  // Falls innerhalb der 5min die KL15 wieder aktiviert wird
			  else if (system_in.KL15 != 1)
			  {
				  setState(Ready);
			  }

			  break;
		  }

		  // State Ausschalten, wenn Standby State laenger als 5min dauert
		  case Ausschalten:
		  {
			  // Alle Ausgaenge ausschalten
			  system_out.systemoutput = 0;
			  highcurrent_out.high_out = 0;
			  leuchten_out.ledoutput = 0;
			  komfort_out.komfortoutput = 0;
			  sdc_in.sdcinput = 0;

			  break;
		  }

		  // Falls kein State zutrifft, dann Kritischer Fehler
		  default:
		  {
			  setStatus(CriticalError);
			  uartTransmit("mStrg Kritischer Fehler While\n!", 30);

			  break;
		  }
	  }

	  // Schreibe WS2812
	  if (WS2812_update == 1)
	  {
		  // Wenn Schreiben moeglich
		  if (WS2812_Send() == 1)
		  {
			  // Solange keine neuen Daten, kein Senden notwendig
			  WS2812_update = 0;
		  }
	  }

	  // Alle Ausgaenge schreiben
	  writeall_outputs();
  }
  /* USER CODE END 3 */
}

void SystemClock_Config(void)
{
  RCC_OscInitTypeDef RCC_OscInitStruct = {0};
  RCC_ClkInitTypeDef RCC_ClkInitStruct = {0};

  /** Configure the main internal regulator output voltage
  */
  __HAL_RCC_PWR_CLK_ENABLE();
  __HAL_PWR_VOLTAGESCALING_CONFIG(PWR_REGULATOR_VOLTAGE_SCALE1);

  /** Initializes the RCC Oscillators according to the specified parameters
  * in the RCC_OscInitTypeDef structure.
  */
  RCC_OscInitStruct.OscillatorType = RCC_OSCILLATORTYPE_HSE;
  RCC_OscInitStruct.HSEState = RCC_HSE_ON;
  RCC_OscInitStruct.PLL.PLLState = RCC_PLL_ON;
  RCC_OscInitStruct.PLL.PLLSource = RCC_PLLSOURCE_HSE;
  RCC_OscInitStruct.PLL.PLLM = 25;
  RCC_OscInitStruct.PLL.PLLN = 432;
  RCC_OscInitStruct.PLL.PLLP = RCC_PLLP_DIV2;
  RCC_OscInitStruct.PLL.PLLQ = 2;
  RCC_OscInitStruct.PLL.PLLR = 2;
  if (HAL_RCC_OscConfig(&RCC_OscInitStruct) != HAL_OK)
  {
    Error_Handler();
  }

  /** Activate the Over-Drive mode
  */
  if (HAL_PWREx_EnableOverDrive() != HAL_OK)
  {
    Error_Handler();
  }

  /** Initializes the CPU, AHB and APB buses clocks
  */
  RCC_ClkInitStruct.ClockType = RCC_CLOCKTYPE_HCLK|RCC_CLOCKTYPE_SYSCLK
                              |RCC_CLOCKTYPE_PCLK1|RCC_CLOCKTYPE_PCLK2;
  RCC_ClkInitStruct.SYSCLKSource = RCC_SYSCLKSOURCE_PLLCLK;
  RCC_ClkInitStruct.AHBCLKDivider = RCC_SYSCLK_DIV1;
  RCC_ClkInitStruct.APB1CLKDivider = RCC_HCLK_DIV4;
  RCC_ClkInitStruct.APB2CLKDivider = RCC_HCLK_DIV2;

  if (HAL_RCC_ClockConfig(&RCC_ClkInitStruct, FLASH_LATENCY_7) != HAL_OK)
  {
    Error_Handler();
  }
}

/* USER CODE BEGIN 4 */
// Checke Shutdown-Circuit
void checkSDC(void)
{
	sdc_in.SDC_OK = true;

	if (((mStrg_state.State == Precharge) || (mStrg_state.State == ReadyToDrive) || (mStrg_state.State == Drive)) && sdc_in.SDC0 == 1)
	{
		setStatus(StateError);
		longerror |= (1 << 0);

		sdc_in.SDC_OK = false;
	}

#if BAMOCAR_AVAILIBLE == 1
	if (sdc_in.BTB_SDC == 1)
	{
		setStatus(StateError);
		longerror |= (1 << 1);

		sdc_in.SDC_OK = false;
	}
#endif

#if BMS_AVAILIBLE == 1
	if (sdc_in.AkkuSDC == 1)
	{
		setStatus(StateError);
		longerror |= (1 << 2);

		sdc_in.SDC_OK = false;
	}
#endif

	if (sdc_in.SDC_OK == true)
	{
		setStatus(StateNormal);
	}
}

// Sortiere CAN Daten
void sortCAN(void)
{
	// Digital-Ausgaenge
	CAN_Output_PaketListe[1].msg.buf[0] = system_out.systemoutput;
	CAN_Output_PaketListe[1].msg.buf[1] = highcurrent_out.high_out;
	CAN_Output_PaketListe[1].msg.buf[2] = (leuchten_out.ledoutput >> 8);
	CAN_Output_PaketListe[1].msg.buf[3] = leuchten_out.ledoutput;
	CAN_Output_PaketListe[1].msg.buf[4] = komfort_out.komfortoutput;
	CAN_Output_PaketListe[1].msg.buf[5] = 0;

	// Digital-Eingaenge
	CAN_Output_PaketListe[2].msg.buf[0] = 0;
	CAN_Output_PaketListe[2].msg.buf[1] = (system_in.systeminput >> 8);
	CAN_Output_PaketListe[2].msg.buf[2] = system_in.systeminput;
	CAN_Output_PaketListe[2].msg.buf[3] = sdc_in.sdcinput;
	CAN_Output_PaketListe[2].msg.buf[4] = (komfort_in.komfortinput >> 8);
	CAN_Output_PaketListe[2].msg.buf[5] = komfort_in.komfortinput;

	// Analogeingaenge
	CAN_Output_PaketListe[3].msg.buf[0] = ADC_VAL[4];
	CAN_Output_PaketListe[3].msg.buf[1] = (ADC_VAL[4] >> 8) | (ADC_VAL[0] << 4);
	CAN_Output_PaketListe[3].msg.buf[2] = (ADC_VAL[0] >> 4);
	CAN_Output_PaketListe[3].msg.buf[3] = gas_mean;
	CAN_Output_PaketListe[3].msg.buf[4] = (gas_mean >> 8) | (ADC_VAL[6] << 4);
	CAN_Output_PaketListe[3].msg.buf[5] = (ADC_VAL[6] >> 4);
	CAN_Output_PaketListe[3].msg.buf[6] = ADC_VAL[7];
	CAN_Output_PaketListe[3].msg.buf[7] = (ADC_VAL[7] >> 8);

	// Motor 280
	CAN_Output_PaketListe[4].msg.buf[0] = motor280.motor280output[0];
	CAN_Output_PaketListe[4].msg.buf[1] = motor280.motor280output[1];
	CAN_Output_PaketListe[4].msg.buf[2] = motor280.motor280output[2];
	CAN_Output_PaketListe[4].msg.buf[3] = motor280.motor280output[3];
	CAN_Output_PaketListe[4].msg.buf[4] = motor280.motor280output[4];
	CAN_Output_PaketListe[4].msg.buf[5] = motor280.motor280output[5];
	CAN_Output_PaketListe[4].msg.buf[6] = motor280.motor280output[6];
	CAN_Output_PaketListe[4].msg.buf[7] = motor280.motor280output[7];

	// Motor 480
	CAN_Output_PaketListe[5].msg.buf[0] = motor480.motor480output[0];
	CAN_Output_PaketListe[5].msg.buf[1] = motor480.motor480output[1];
	CAN_Output_PaketListe[5].msg.buf[2] = motor480.motor480output[2];
	CAN_Output_PaketListe[5].msg.buf[3] = motor480.motor480output[3];
	CAN_Output_PaketListe[5].msg.buf[4] = motor480.motor480output[4];
	CAN_Output_PaketListe[5].msg.buf[5] = motor480.motor480output[5];
	CAN_Output_PaketListe[5].msg.buf[6] = motor480.motor480output[6];
	CAN_Output_PaketListe[5].msg.buf[7] = motor480.motor480output[7];

	// Temperatureingaenge
	CAN_Output_PaketListe[6].msg.buf[0] = ADC_VAL[2];
	CAN_Output_PaketListe[6].msg.buf[1] = (ADC_VAL[2] >> 8) | (ADC_VAL[3] << 4);
	CAN_Output_PaketListe[6].msg.buf[2] = (ADC_VAL[3] >> 4);
	CAN_Output_PaketListe[6].msg.buf[3] = ADC_VAL[8];
	CAN_Output_PaketListe[6].msg.buf[4] = (ADC_VAL[8] >> 8) | (ADC_VAL[1] << 4);
	CAN_Output_PaketListe[6].msg.buf[5] = (ADC_VAL[1] >> 4);
	CAN_Output_PaketListe[6].msg.buf[6] = ADC_VAL[5];
	CAN_Output_PaketListe[6].msg.buf[7] = (ADC_VAL[5] >> 8);

	// Motor Status
	CAN_Output_PaketListe[7].msg.buf[0] = mStrg_state.status;
	CAN_Output_PaketListe[7].msg.buf[1] = longwarning;
	CAN_Output_PaketListe[7].msg.buf[2] = longerror;
	CAN_Output_PaketListe[7].msg.buf[3] = can_online;
}

// Set Statemaschine
void setState(uint8_t State)
{
	switch (State)
	{
		case Ready:
		{
			mStrg_state.State = Ready;
			uartTransmit("Ready\n", 6);

			break;
		}
		case KL15:
		{
			mStrg_state.State = KL15;
			uartTransmit("KL15\n", 5);

			break;
		}
		case Anlassen:
		{
			mStrg_state.State = Anlassen;
			uartTransmit("Anlassen\n", 9);

			break;
		}
		case Precharge:
		{
			mStrg_state.State = Precharge;
			uartTransmit("Precharge\n", 10);

			break;
		}
		case ReadyToDrive:
		{
			mStrg_state.State = ReadyToDrive;
			uartTransmit("ReadyToDrive\n", 13);

			break;
		}
		case Drive:
		{
			mStrg_state.State = Drive;
			uartTransmit("Drive\n", 6);

			break;
		}
		case Standby:
		{
			mStrg_state.State = Standby;
			uartTransmit("Standby\n", 8);

			break;
		}
		case Ausschalten:
		{
			mStrg_state.State = Ausschalten;
			uartTransmit("Ausschalten\n", 12);

			break;
		}
		default:
		{
			break;
		}
	}
}

// Set Status der Statemaschine
void setStatus(uint8_t Status)
{
	switch (Status & 0xF0)
	{
		case StateNormal:
		{
			if (mStrg_state.status & StateWarning)
			{
				if (millis() > (timeWarning + WARNING_RESET))
				{
					mStrg_state.status = (Status | mStrg_state.State);

					longwarning = 0;
					longerror = 0;
				}

				break;
			}
		}
		case StateWarning:
		{
			timeWarning = millis();

			if (mStrg_state.status & StateError)
			{
				if (millis() > (timeError + ERROR_RESET))
				{
					mStrg_state.status = (StateWarning | mStrg_state.State);
				}

				break;
			}
		}
		case StateError:
		{
			timeError = millis();

			if (mStrg_state.status & CriticalError)
			{
				break;
			}
		}
		case CriticalError:
		{
			mStrg_state.status = (Status | mStrg_state.State);
			break;
		}
		default:
		{
			mStrg_state.status = (CriticalError | mStrg_state.State);
			uartTransmit("mStrg Kritischer Fehler Statemaschine\n!", 38);
			break;
		}
	}
}

// Timer-Interrupt: Timer ist uebergelaufen
void HAL_TIM_PeriodElapsedCallback(TIM_HandleTypeDef *htim)
{
	// Kontrolliere welcher Timer den Ueberlauf ausgeloest hat
	if (htim == &htim6)																	// Wenn Timer 6 den ueberlauf ausgeloest hat
	{
		millisekunden_flag = 1;															// Setze Millisekunden Flag
	}
}
/* USER CODE END 4 */

void Error_Handler(void)
{
  /* USER CODE BEGIN Error_Handler_Debug */
	/* User can add his own implementation to report the HAL error return state */
	__disable_irq();														// Interrupts deaktivieren

	// Schalte Fehler LED ein
	leuchten_out.RedLed = 1;												// Setze Variable
	HAL_GPIO_WritePin(RED_LED_GPIO_Port, RED_LED_Pin, leuchten_out.RedLed);	// Fehler LED einschalten

	// Schalte Ok LED aus
	leuchten_out.GreenLed = 0;												// Zuruechsetzen Variable
	HAL_GPIO_WritePin(GREEN_LED_GPIO_Port, GREEN_LED_Pin, leuchten_out.GreenLed);// Fehler LED ausschalten

	// Sende Nachricht auf Uart-Interface
#ifdef DEBUG
#define STRING_ERROR_HANDLER			"Error Handler wird ausgefuehrt!!!"
	uartTransmit(STRING_ERROR_HANDLER, sizeof(STRING_ERROR_HANDLER));
#endif
	// Beginne Endlosschleife nachdem Fehler aufgetreten ist
	while (1);
  /* USER CODE END Error_Handler_Debug */
}
